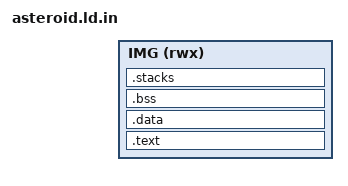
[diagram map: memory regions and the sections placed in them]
/* The bootloader copies the image to IMG_BASE and jumps to its first word.
 * Everything the firmware owns sits in the first DRAM bank; the inherited
 * framebuffer and the persistent log are fixed addresses elsewhere. Code,
 * data, bss and stacks must end below IMG_END, where the bootloader puts the
 * device tree. The Makefile runs this through the C preprocessor. */
#include "soc/memmap.h"
MEMORY
{
    IMG (rwx) : ORIGIN = IMG_BASE, LENGTH = IMG_END - IMG_BASE
}
ENTRY(_start)
SECTIONS
{
    .text : {
        KEEP(*(.vectors))
        *(.text*)
        *(.rodata*)
        . = ALIGN(4);
    } > IMG
    .data : { . = ALIGN(4); *(.data*) . = ALIGN(4); } > IMG
    __image_end = .;
    .bss (NOLOAD) : {
        . = ALIGN(4);
        __bss_start = .;
        *(.bss*) *(COMMON)
        . = ALIGN(16384);
        __mmu_l1 = .;
        . += 16384;
        . = ALIGN(4);
        __bss_end = .;
    } > IMG
    .stacks (NOLOAD) : {
        . = ALIGN(16);
        . += 256;   __stack_fiq_top = .;
        . += 1024;  __stack_und_top = .;
        . += 4096;  __stack_abt_top = .;
        . += 4096;  __stack_irq_top = .;
        . += 131072; __stack_svc_top = .;
    } > IMG
    __ram_end = .;
    /DISCARD/ : { *(.ARM.exidx*) *(.ARM.extab*) *(.comment) }
}
